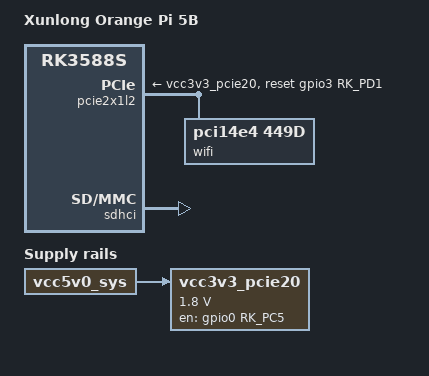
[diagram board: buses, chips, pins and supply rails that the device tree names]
// SPDX-License-Identifier: (GPL-2.0+ OR MIT)

/dts-v1/;

#include "rk3588s-orangepi-5.dtsi"

/ {
	model = "Xunlong Orange Pi 5B";
	compatible = "xunlong,orangepi-5b", "rockchip,rk3588s";

	aliases {
		mmc0 = &sdhci;
		mmc1 = &sdmmc;
	};

	vcc3v3_pcie20: regulator-vcc3v3-pcie20 {
		compatible = "regulator-fixed";
		enable-active-high;
		gpios = <&gpio0 RK_PC5 GPIO_ACTIVE_HIGH>;
		regulator-name = "vcc3v3_pcie20";
		regulator-boot-on;
		regulator-min-microvolt = <1800000>;
		regulator-max-microvolt = <1800000>;
		startup-delay-us = <50000>;
		vin-supply = <&vcc5v0_sys>;
	};
};

&pcie2x1l2 {
	reset-gpios = <&gpio3 RK_PD1 GPIO_ACTIVE_HIGH>;
	vpcie3v3-supply = <&vcc3v3_pcie20>;
	status = "okay";

	pcie@0,0 {
		reg = <0x400000 0 0 0 0>;
		#address-cells = <3>;
		#size-cells = <2>;
		ranges;
		device_type = "pci";
		bus-range = <0x40 0x4f>;
		wifi: wifi@0,0 {
			compatible = "pci14e4,449d";
			reg = <0x410000 0 0 0 0>;
			clocks = <&hym8563>;
			clock-names = "lpo";
		};
	};
};

&sdhci {
	status = "okay";
};
